AUTOSAR XML (schema 3.1.2)
package /Components/SWC_TqDem
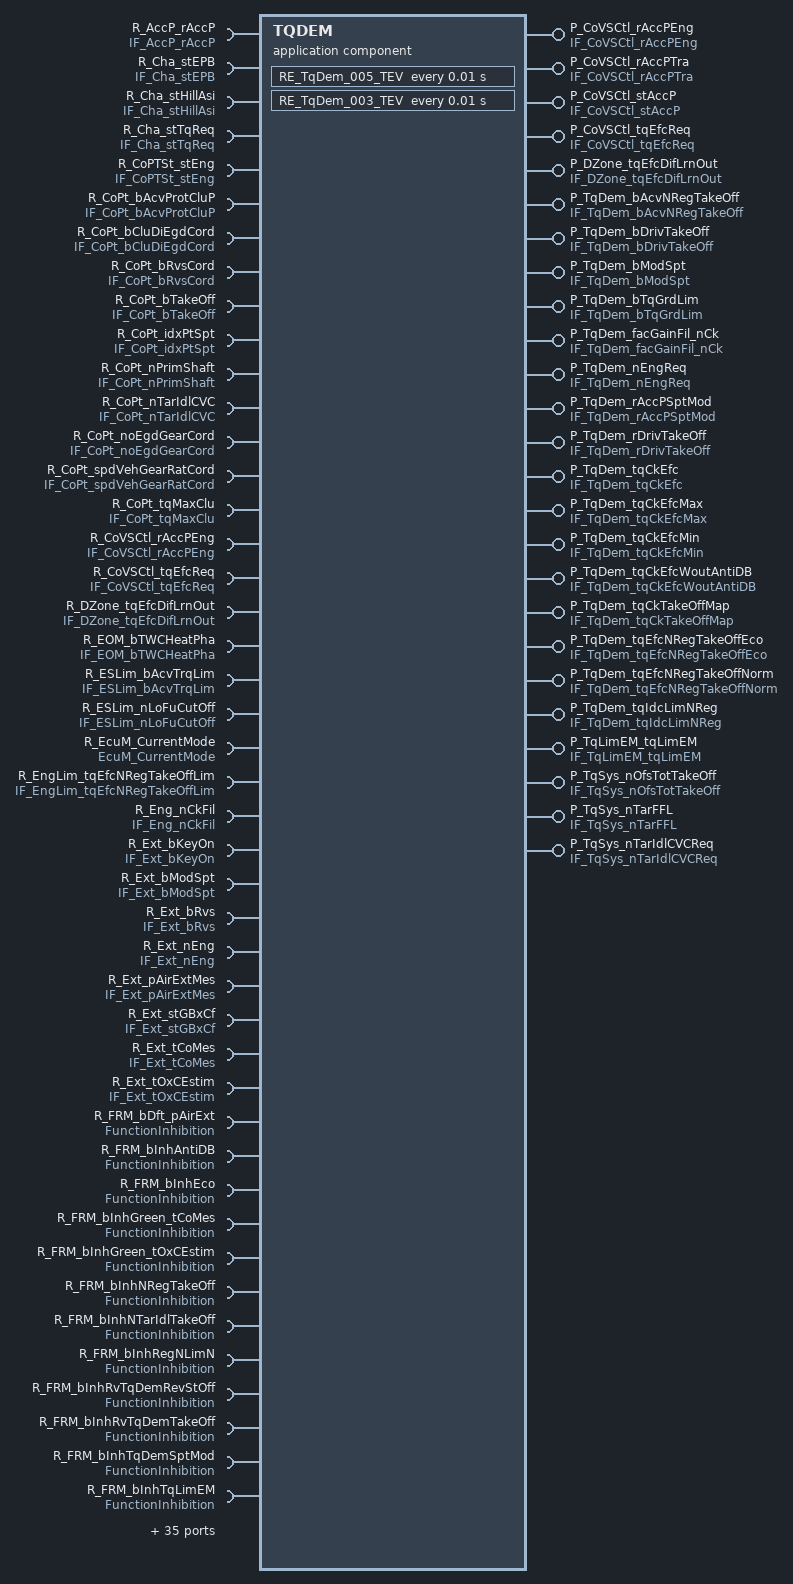
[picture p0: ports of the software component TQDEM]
  application software component type TQDEM  # TqDem
    25 x provide port:
      P_CoVSCtl_rAccPEng: unqueued-sender-com-spec{data-element=CoVSCtl_rAccPEng, can-invalidate=false, init-value=ConstantValue}, provided-interface=IF_CoVSCtl_rAccPEng
      P_CoVSCtl_rAccPTra: unqueued-sender-com-spec{data-element=CoVSCtl_rAccPTra, can-invalidate=false, init-value=ConstantValue1}, provided-interface=IF_CoVSCtl_rAccPTra
      P_CoVSCtl_stAccP: unqueued-sender-com-spec{data-element=CoVSCtl_stAccP, can-invalidate=false, init-value=ConstantValue3}, provided-interface=IF_CoVSCtl_stAccP
      P_CoVSCtl_tqEfcReq: unqueued-sender-com-spec{data-element=CoVSCtl_tqEfcReq, can-invalidate=false, init-value=ConstantValue5}, provided-interface=IF_CoVSCtl_tqEfcReq
      P_DZone_tqEfcDifLrnOut: unqueued-sender-com-spec{data-element=DZone_tqEfcDifLrnOut, can-invalidate=false, init-value=C_SInt16_0}, provided-interface=IF_DZone_tqEfcDifLrnOut
      P_TqDem_bAcvNRegTakeOff: unqueued-sender-com-spec{data-element=TqDem_bAcvNRegTakeOff, can-invalidate=false, init-value=C_Boolean_True}, provided-interface=IF_TqDem_bAcvNRegTakeOff
      P_TqDem_bDrivTakeOff: unqueued-sender-com-spec{data-element=TqDem_bDrivTakeOff, can-invalidate=false, init-value=ConstantValue7}, provided-interface=IF_TqDem_bDrivTakeOff
      P_TqDem_bModSpt: unqueued-sender-com-spec{data-element=TqDem_bModSpt, can-invalidate=false, init-value=ConstantValue9}, provided-interface=IF_TqDem_bModSpt
      P_TqDem_bTqGrdLim: unqueued-sender-com-spec{data-element=TqDem_bTqGrdLim, can-invalidate=false, init-value=ConstantValue11}, provided-interface=IF_TqDem_bTqGrdLim
      P_TqDem_facGainFil_nCk: unqueued-sender-com-spec{data-element=TqDem_facGainFil_nCk, can-invalidate=false, init-value=ConstantValue13}, provided-interface=IF_TqDem_facGainFil_nCk
      P_TqDem_nEngReq: unqueued-sender-com-spec{data-element=TqDem_nEngReq, can-invalidate=false, init-value=C_UInt16_750}, provided-interface=IF_TqDem_nEngReq
      P_TqDem_rAccPSptMod: unqueued-sender-com-spec{data-element=TqDem_rAccPSptMod, can-invalidate=false, init-value=C_UInt16_0}, provided-interface=IF_TqDem_rAccPSptMod
      P_TqDem_rDrivTakeOff: unqueued-sender-com-spec{data-element=TqDem_rDrivTakeOff, can-invalidate=false, init-value=C_UInt16_015}, provided-interface=IF_TqDem_rDrivTakeOff
      P_TqDem_tqCkEfc: unqueued-sender-com-spec{data-element=TqDem_tqCkEfc, can-invalidate=false, init-value=ConstantValue17}, provided-interface=IF_TqDem_tqCkEfc
      P_TqDem_tqCkEfcMax: unqueued-sender-com-spec{data-element=TqDem_tqCkEfcMax, can-invalidate=false, init-value=C_SInt16_019}, provided-interface=IF_TqDem_tqCkEfcMax
      P_TqDem_tqCkEfcMin: unqueued-sender-com-spec{data-element=TqDem_tqCkEfcMin, can-invalidate=false, init-value=C_SInt16_021}, provided-interface=IF_TqDem_tqCkEfcMin
      P_TqDem_tqCkEfcWoutAntiDB: unqueued-sender-com-spec{data-element=TqDem_tqCkEfcWoutAntiDB, can-invalidate=false, init-value=C_SInt16_023}, provided-interface=IF_TqDem_tqCkEfcWoutAntiDB
      P_TqDem_tqCkTakeOffMap: unqueued-sender-com-spec{data-element=TqDem_tqCkTakeOffMap, can-invalidate=false, init-value=C_SInt16_025}, provided-interface=IF_TqDem_tqCkTakeOffMap
      P_TqDem_tqEfcNRegTakeOffEco: unqueued-sender-com-spec{data-element=TqDem_tqEfcNRegTakeOffEco, can-invalidate=false, init-value=C_t_TqDem_Tab2_S16_0}, provided-interface=IF_TqDem_tqEfcNRegTakeOffEco
      P_TqDem_tqEfcNRegTakeOffNorm: unqueued-sender-com-spec{data-element=TqDem_tqEfcNRegTakeOffNorm, can-invalidate=false, init-value=C_t_TqDem_Tab2_S16_027}, provided-interface=IF_TqDem_tqEfcNRegTakeOffNorm
      P_TqDem_tqIdcLimNReg: unqueued-sender-com-spec{data-element=TqDem_tqIdcLimNReg, can-invalidate=false, init-value=ConstantValue29}, provided-interface=IF_TqDem_tqIdcLimNReg
      P_TqLimEM_tqLimEM: unqueued-sender-com-spec{data-element=TqLimEM_tqLimEM, can-invalidate=false, init-value=ConstantValue31}, provided-interface=IF_TqLimEM_tqLimEM
      P_TqSys_nOfsTotTakeOff: unqueued-sender-com-spec{data-element=TqSys_nOfsTotTakeOff, can-invalidate=false, init-value=C_UInt16_033}, provided-interface=IF_TqSys_nOfsTotTakeOff
      P_TqSys_nTarFFL: unqueued-sender-com-spec{data-element=TqSys_nTarFFL, can-invalidate=false, init-value=C_UInt16_035}, provided-interface=IF_TqSys_nTarFFL
      P_TqSys_nTarIdlCVCReq: unqueued-sender-com-spec{data-element=TqSys_nTarIdlCVCReq, can-invalidate=false, init-value=C_UInt16_037}, provided-interface=IF_TqSys_nTarIdlCVCReq
    79 x require port:
      R_AccP_rAccP: unqueued-receiver-com-spec{data-element=AccP_rAccP, init-value=ConstantValue39, resync-time=0}, required-interface=IF_AccP_rAccP
      R_Cha_stEPB: unqueued-receiver-com-spec{data-element=Cha_stEPB, init-value=ConstantValue41, resync-time=0}, required-interface=IF_Cha_stEPB
      R_Cha_stHillAsi: unqueued-receiver-com-spec{data-element=Cha_stHillAsi, init-value=C_UInt8_0, resync-time=0}, required-interface=IF_Cha_stHillAsi
      R_Cha_stTqReq: unqueued-receiver-com-spec{data-element=Cha_stTqReq, init-value=ConstantValue43, resync-time=0}, required-interface=IF_Cha_stTqReq
      R_CoPTSt_stEng: unqueued-receiver-com-spec{data-element=CoPTSt_stEng, init-value=ConstantValue45, resync-time=0}, required-interface=IF_CoPTSt_stEng
      R_CoPt_bAcvProtCluP: unqueued-receiver-com-spec{data-element=CoPt_bAcvProtCluP, init-value=C_Boolean_False, resync-time=0}, required-interface=IF_CoPt_bAcvProtCluP
      R_CoPt_bCluDiEgdCord: unqueued-receiver-com-spec{data-element=CoPt_bCluDiEgdCord, init-value=ConstantValue47, resync-time=0}, required-interface=IF_CoPt_bCluDiEgdCord
      R_CoPt_bRvsCord: unqueued-receiver-com-spec{data-element=CoPt_bRvsCord, init-value=ConstantValue49, resync-time=0}, required-interface=IF_CoPt_bRvsCord
      R_CoPt_bTakeOff: unqueued-receiver-com-spec{data-element=CoPt_bTakeOff, init-value=C_Boolean_False51, resync-time=0}, required-interface=IF_CoPt_bTakeOff
      R_CoPt_idxPtSpt: unqueued-receiver-com-spec{data-element=CoPt_idxPtSpt, init-value=C_UInt8_053, resync-time=0}, required-interface=IF_CoPt_idxPtSpt
      R_CoPt_nPrimShaft: unqueued-receiver-com-spec{data-element=CoPt_nPrimShaft, init-value=C_UInt16_055, resync-time=0}, required-interface=IF_CoPt_nPrimShaft
      R_CoPt_nTarIdlCVC: unqueued-receiver-com-spec{data-element=CoPt_nTarIdlCVC, init-value=C_UInt16_057, resync-time=0}, required-interface=IF_CoPt_nTarIdlCVC
      R_CoPt_noEgdGearCord: unqueued-receiver-com-spec{data-element=CoPt_noEgdGearCord, init-value=ConstantValue59, resync-time=0}, required-interface=IF_CoPt_noEgdGearCord
      R_CoPt_spdVehGearRatCord: unqueued-receiver-com-spec{data-element=CoPt_spdVehGearRatCord, init-value=ConstantValue61, resync-time=0}, required-interface=IF_CoPt_spdVehGearRatCord
      R_CoPt_tqMaxClu: unqueued-receiver-com-spec{data-element=CoPt_tqMaxClu, init-value=C_SInt16_m32000, resync-time=0}, required-interface=IF_CoPt_tqMaxClu
      R_CoVSCtl_rAccPEng: unqueued-receiver-com-spec{data-element=CoVSCtl_rAccPEng, init-value=ConstantValue, resync-time=0}, required-interface=IF_CoVSCtl_rAccPEng
      R_CoVSCtl_tqEfcReq: unqueued-receiver-com-spec{data-element=CoVSCtl_tqEfcReq, init-value=ConstantValue63, resync-time=0}, required-interface=IF_CoVSCtl_tqEfcReq
      R_DZone_tqEfcDifLrnOut: unqueued-receiver-com-spec{data-element=DZone_tqEfcDifLrnOut, init-value=C_SInt16_m3200065, resync-time=0}, required-interface=IF_DZone_tqEfcDifLrnOut
      R_EOM_bTWCHeatPha: unqueued-receiver-com-spec{data-element=EOM_bTWCHeatPha, init-value=ConstantValue67, resync-time=0}, required-interface=IF_EOM_bTWCHeatPha
      R_ESLim_bAcvTrqLim: unqueued-receiver-com-spec{data-element=ESLim_bAcvTrqLim, init-value=ConstantValue69, resync-time=0}, required-interface=IF_ESLim_bAcvTrqLim
      R_ESLim_nLoFuCutOff: unqueued-receiver-com-spec{data-element=ESLim_nLoFuCutOff, init-value=C_UInt16_071, resync-time=0}, required-interface=IF_ESLim_nLoFuCutOff
      R_EcuM_CurrentMode: required-interface=EcuM_CurrentMode  # Requirement: 01552_09_00532-SSTG-C007(2)
      R_EngLim_tqEfcNRegTakeOffLim: unqueued-receiver-com-spec{data-element=EngLim_tqEfcNRegTakeOffLim, init-value=C_SInt16_m3200073, resync-time=0}, required-interface=IF_EngLim_tqEfcNRegTakeOffLim
      R_Eng_nCkFil: unqueued-receiver-com-spec{data-element=Eng_nCkFil, init-value=ConstantValue75, resync-time=0}, required-interface=IF_Eng_nCkFil
      R_Ext_bKeyOn: unqueued-receiver-com-spec{data-element=Ext_bKeyOn, init-value=C_Boolean_False77, resync-time=0}, required-interface=IF_Ext_bKeyOn
      R_Ext_bModSpt: unqueued-receiver-com-spec{data-element=Ext_bModSpt, init-value=C_Boolean_False79, resync-time=0}, required-interface=IF_Ext_bModSpt
      R_Ext_bRvs: unqueued-receiver-com-spec{data-element=Ext_bRvs, init-value=ConstantValue81, resync-time=0}, required-interface=IF_Ext_bRvs
      R_Ext_nEng: unqueued-receiver-com-spec{data-element=Ext_nEng, init-value=ConstantValue83, resync-time=0}, required-interface=IF_Ext_nEng
      R_Ext_pAirExtMes: unqueued-receiver-com-spec{data-element=Ext_pAirExtMes, init-value=ConstantValue85, resync-time=0}, required-interface=IF_Ext_pAirExtMes
      R_Ext_stGBxCf: unqueued-receiver-com-spec{data-element=Ext_stGBxCf, init-value=ConstantValue87, resync-time=0}, required-interface=IF_Ext_stGBxCf
      R_Ext_tCoMes: unqueued-receiver-com-spec{data-element=Ext_tCoMes, init-value=ConstantValue89, resync-time=0}, required-interface=IF_Ext_tCoMes
      R_Ext_tOxCEstim: unqueued-receiver-com-spec{data-element=Ext_tOxCEstim, init-value=C_SInt16_m50, resync-time=0}, required-interface=IF_Ext_tOxCEstim
      R_FRM_bDft_pAirExt: required-interface=FunctionInhibition
      R_FRM_bInhAntiDB: required-interface=FunctionInhibition
      R_FRM_bInhEco: required-interface=FunctionInhibition
      R_FRM_bInhGreen_tCoMes: required-interface=FunctionInhibition
      R_FRM_bInhGreen_tOxCEstim: required-interface=FunctionInhibition
      R_FRM_bInhNRegTakeOff: required-interface=FunctionInhibition
      R_FRM_bInhNTarIdlTakeOff: required-interface=FunctionInhibition
      R_FRM_bInhRegNLimN: required-interface=FunctionInhibition
      R_FRM_bInhRvTqDemRevStOff: required-interface=FunctionInhibition
      R_FRM_bInhRvTqDemTakeOff: required-interface=FunctionInhibition
      R_FRM_bInhTqDemSptMod: required-interface=FunctionInhibition
      R_FRM_bInhTqLimEM: required-interface=FunctionInhibition
      R_TqAdp_bFrzAdpACOn: unqueued-receiver-com-spec{data-element=TqAdp_bFrzAdpACOn, init-value=ConstantValue91, resync-time=0}, required-interface=IF_TqAdp_bFrzAdpACOn
      R_TqAdp_bFrzAdpAltOn: unqueued-receiver-com-spec{data-element=TqAdp_bFrzAdpAltOn, init-value=ConstantValue93, resync-time=0}, required-interface=IF_TqAdp_bFrzAdpAltOn
      R_TqAdp_bFrzAdpCnvOn: unqueued-receiver-com-spec{data-element=TqAdp_bFrzAdpCnvOn, init-value=ConstantValue95, resync-time=0}, required-interface=IF_TqAdp_bFrzAdpCnvOn
      R_TqAdp_bFrzAdpStgPmpOn: unqueued-receiver-com-spec{data-element=TqAdp_bFrzAdpStgPmpOn, init-value=ConstantValue97, resync-time=0}, required-interface=IF_TqAdp_bFrzAdpStgPmpOn
      R_TqCmp_tqSumLossCmp: unqueued-receiver-com-spec{data-element=TqCmp_tqSumLossCmp, init-value=ConstantValue99, resync-time=0}, required-interface=IF_TqCmp_tqSumLossCmp
      R_TqDem_GetTimer_1ms_U32: required-interface=IF_CS_FRunTime_1MS_U32
      R_TqDem_bAcvNRegTakeOff: unqueued-receiver-com-spec{data-element=TqDem_bAcvNRegTakeOff, init-value=C_Boolean_False101, resync-time=0}, required-interface=IF_TqDem_bAcvNRegTakeOff
      R_TqDem_rAccPSptMod: unqueued-receiver-com-spec{data-element=TqDem_rAccPSptMod, init-value=C_UInt16_0, resync-time=0}, required-interface=IF_TqDem_rAccPSptMod
      R_TqDem_rDrivTakeOff: unqueued-receiver-com-spec{data-element=TqDem_rDrivTakeOff, init-value=C_UInt16_0103, resync-time=0}, required-interface=IF_TqDem_rDrivTakeOff
      R_TqDem_tqCkEfc: unqueued-receiver-com-spec{data-element=TqDem_tqCkEfc, init-value=ConstantValue105, resync-time=0}, required-interface=IF_TqDem_tqCkEfc
      R_TqDem_tqCkEfcWoutAntiDB: unqueued-receiver-com-spec{data-element=TqDem_tqCkEfcWoutAntiDB, init-value=C_SInt16_m32000107, resync-time=0}, required-interface=IF_TqDem_tqCkEfcWoutAntiDB
      R_TqDem_tqEfcNRegTakeOffEco: unqueued-receiver-com-spec{data-element=TqDem_tqEfcNRegTakeOffEco, init-value=C_t_TqDem_Tab2_S16_m32000, resync-time=0}, required-interface=IF_TqDem_tqEfcNRegTakeOffEco
      R_TqDem_tqEfcNRegTakeOffNorm: unqueued-receiver-com-spec{data-element=TqDem_tqEfcNRegTakeOffNorm, init-value=C_t_TqDem_Tab2_S16_m32000109, resync-time=0}, required-interface=IF_TqDem_tqEfcNRegTakeOffNorm
      R_TqSys_bAcvAntiStall: unqueued-receiver-com-spec{data-element=TqSys_bAcvAntiStall, init-value=ConstantValue111, resync-time=0}, required-interface=IF_TqSys_bAcvAntiStall
      R_TqSys_bAcvAntiStallMan: unqueued-receiver-com-spec{data-element=TqSys_bAcvAntiStallMan, init-value=ConstantValue113, resync-time=0}, required-interface=IF_TqSys_bAcvAntiStallMan
      R_TqSys_bEngNOnIdl: unqueued-receiver-com-spec{data-element=TqSys_bEngNOnIdl, init-value=ConstantValue115, resync-time=0}, required-interface=IF_TqSys_bEngNOnIdl
      R_TqSys_bInhTqDemSptMod: unqueued-receiver-com-spec{data-element=TqSys_bInhTqDemSptMod, init-value=C_Boolean_False117, resync-time=0}, required-interface=IF_TqSys_bInhTqDemSptMod
      R_TqSys_bTypFu: unqueued-receiver-com-spec{data-element=TqSys_bTypFu, init-value=ConstantValue119, resync-time=0}, required-interface=IF_TqSys_bTypFu
      R_TqSys_nOfsFFL: unqueued-receiver-com-spec{data-element=TqSys_nOfsFFL, init-value=C_UInt16_0121, resync-time=0}, required-interface=IF_TqSys_nOfsFFL
      R_TqSys_nOfsLauchIdlTakeOff: unqueued-receiver-com-spec{data-element=TqSys_nOfsLauchIdlTakeOff, init-value=C_UInt16_0123, resync-time=0}, required-interface=IF_TqSys_nOfsLauchIdlTakeOff
      R_TqSys_nOfsTotTakeOff: unqueued-receiver-com-spec{data-element=TqSys_nOfsTotTakeOff, init-value=C_UInt16_0125, resync-time=0}, required-interface=IF_TqSys_nOfsTotTakeOff
      R_TqSys_nTarIdl: unqueued-receiver-com-spec{data-element=TqSys_nTarIdl, init-value=ConstantValue127, resync-time=0}, required-interface=IF_TqSys_nTarIdl
      R_TqSys_nTarIdlFil: unqueued-receiver-com-spec{data-element=TqSys_nTarIdlFil, init-value=C_UInt16_0129, resync-time=0}, required-interface=IF_TqSys_nTarIdlFil
      R_TqSys_nTarIdlNeut: unqueued-receiver-com-spec{data-element=TqSys_nTarIdlNeut, init-value=C_UInt16_0131, resync-time=0}, required-interface=IF_TqSys_nTarIdlNeut
      R_TqSys_tqCkIdlCmn: unqueued-receiver-com-spec{data-element=TqSys_tqCkIdlCmn, init-value=ConstantValue133, resync-time=0}, required-interface=IF_TqSys_tqCkIdlCmn
      R_TqSys_tqIdcAirLimCordWiRes: unqueued-receiver-com-spec{data-element=TqSys_tqIdcAirLimCordWiRes, init-value=ConstantValue135, resync-time=0}, required-interface=IF_TqSys_tqIdcAirLimCordWiRes
      R_TreatTenms_nCkGrd: unqueued-receiver-com-spec{data-element=TreatTenms_nCkGrd, init-value=C_SInt16_m32000137, resync-time=0}, required-interface=IF_TreatTenms_nCkGrd
      R_UCE_stWkuMainRelSt: required-interface=IF_UCE_stWkuMainRelSt  # Requirement: 01552_09_00532-SSTG-C011(1)
      R_VSCtl_rAccPEngMax: unqueued-receiver-com-spec{data-element=VSCtl_rAccPEngMax, init-value=C_UInt16_0139, resync-time=0}, required-interface=IF_VSCtl_rAccPEngMax
      R_VSCtl_rAccPEngMin: unqueued-receiver-com-spec{data-element=VSCtl_rAccPEngMin, init-value=C_UInt16_0141, resync-time=0}, required-interface=IF_VSCtl_rAccPEngMin
      R_VSCtl_rAccPTraMax: unqueued-receiver-com-spec{data-element=VSCtl_rAccPTraMax, init-value=C_UInt16_0143, resync-time=0}, required-interface=IF_VSCtl_rAccPTraMax
      R_VSCtl_rAccPTraMin: unqueued-receiver-com-spec{data-element=VSCtl_rAccPTraMin, init-value=C_UInt16_0145, resync-time=0}, required-interface=IF_VSCtl_rAccPTraMin
      R_VSCtl_tqCkEfcMaxReq: unqueued-receiver-com-spec{data-element=VSCtl_tqCkEfcMaxReq, init-value=C_SInt16_m32000147, resync-time=0}, required-interface=IF_VSCtl_tqCkEfcMaxReq
      R_VSCtl_tqCkEfcMinReq: unqueued-receiver-com-spec{data-element=VSCtl_tqCkEfcMinReq, init-value=C_SInt16_m32000149, resync-time=0}, required-interface=IF_VSCtl_tqCkEfcMinReq
      R_Veh_spdVeh: unqueued-receiver-com-spec{data-element=Veh_spdVeh, init-value=ConstantValue151, resync-time=0}, required-interface=IF_Veh_spdVeh
  94 x constant specification:
    C_Boolean_False
      value:
        boolean literal C_Boolean_False: type=DT_CoPt_bAcvProtCluP, value=false
    C_Boolean_False101
      value:
        boolean literal C_Boolean_False101: type=DT_TqDem_bAcvNRegTakeOff, value=true
    C_Boolean_False117
      value:
        boolean literal C_Boolean_False117: type=DT_TqSys_bInhTqDemSptMod, value=false
    C_Boolean_False51
      value:
        boolean literal C_Boolean_False51: type=DT_CoPt_bTakeOff, value=false
    C_Boolean_False77
      value:
        boolean literal C_Boolean_False77: type=DT_Ext_bKeyOn, value=false
    C_Boolean_False79
      value:
        boolean literal C_Boolean_False79: type=DT_Ext_bModSpt, value=false
    C_Boolean_True
      value:
        boolean literal C_Boolean_True: type=DT_TqDem_bAcvNRegTakeOff, value=true
    C_SInt16_0
      value:
        integer literal C_SInt16_0: type=DT_DZone_tqEfcDifLrnOut, value=0
    C_SInt16_0153
      value:
        integer literal C_SInt16_0153: type=DT_TqDem_tqCkEfcDeltaEcoNorm, value=0
    C_SInt16_0155
      value:
        integer literal C_SInt16_0155: type=DT_TqDem_tqCkEfcDeltaTakeOff, value=0
    C_SInt16_019
      value:
        integer literal C_SInt16_019: type=DT_TqDem_tqCkEfcMax, value=0
    C_SInt16_021
      value:
        integer literal C_SInt16_021: type=DT_TqDem_tqCkEfcMin, value=0
    C_SInt16_023
      value:
        integer literal C_SInt16_023: type=DT_TqDem_tqCkEfcWoutAntiDB, value=0
    C_SInt16_025
      value:
        integer literal C_SInt16_025: type=DT_TqDem_tqCkTakeOffMap, value=0
    C_SInt16_m32000
      value:
        integer literal C_SInt16_m32000: type=DT_CoPt_tqMaxClu, value=0
    C_SInt16_m32000107
      value:
        integer literal C_SInt16_m32000107: type=DT_TqDem_tqCkEfcWoutAntiDB, value=0
    C_SInt16_m32000137
      value:
        integer literal C_SInt16_m32000137: type=DT_TreatTenms_nCkGrd, value=0
    C_SInt16_m32000147
      value:
        integer literal C_SInt16_m32000147: type=DT_VSCtl_tqCkEfcMaxReq, value=32000
    C_SInt16_m32000149
      value:
        integer literal C_SInt16_m32000149: type=DT_VSCtl_tqCkEfcMinReq, value=-32000
    C_SInt16_m3200065
      value:
        integer literal C_SInt16_m3200065: type=DT_DZone_tqEfcDifLrnOut, value=0
    C_SInt16_m3200073
      value:
        integer literal C_SInt16_m3200073: type=DT_EngLim_tqEfcNRegTakeOffLim, value=32000
    C_SInt16_m50
      value:
        integer literal C_SInt16_m50: type=DT_Ext_tOxCEstim, value=1000
    C_t_TqDem_Tab2_S16_0
      value:
        array specification C_t_TqDem_Tab2_S16_0: type=t_TqDem_Tab2_S16
          integer literal Value_0: type=DT_TqDem_tqEfcNRegTakeOffEco, value=0
          integer literal Value_1: type=DT_TqDem_tqEfcNRegTakeOffEco, value=0
    C_t_TqDem_Tab2_S16_027
      value:
        array specification C_t_TqDem_Tab2_S16_027: type=t_TqDem_Tab2_S16_m1
          integer literal Value_0: type=DT_TqDem_tqEfcNRegTakeOffNorm, value=0
          integer literal Value_1: type=DT_TqDem_tqEfcNRegTakeOffNorm, value=0
    C_t_TqDem_Tab2_S16_m32000
      value:
        array specification C_t_TqDem_Tab2_S16_m32000: type=t_TqDem_Tab2_S16
          integer literal Value_0: type=DT_TqDem_tqEfcNRegTakeOffEco, value=0
          integer literal Value_1: type=DT_TqDem_tqEfcNRegTakeOffEco, value=0
    C_t_TqDem_Tab2_S16_m32000109
      value:
        array specification C_t_TqDem_Tab2_S16_m32000109: type=t_TqDem_Tab2_S16_m1
          integer literal Value_0: type=DT_TqDem_tqEfcNRegTakeOffNorm, value=0
          integer literal Value_1: type=DT_TqDem_tqEfcNRegTakeOffNorm, value=0
    C_UInt16_0
      value:
        integer literal C_UInt16_0: type=DT_TqDem_rAccPSptMod, value=0
    C_UInt16_0103
      value:
        integer literal C_UInt16_0103: type=DT_TqDem_rDrivTakeOff, value=0
    C_UInt16_0121
      value:
        integer literal C_UInt16_0121: type=DT_TqSys_nOfsFFL, value=0
    C_UInt16_0123
      value:
        integer literal C_UInt16_0123: type=DT_TqSys_nOfsLauchIdlTakeOff, value=0
    C_UInt16_0125
      value:
        integer literal C_UInt16_0125: type=DT_TqSys_nOfsTotTakeOff, value=0
    C_UInt16_0129
      value:
        integer literal C_UInt16_0129: type=DT_TqSys_nTarIdlFil, value=0
    C_UInt16_0131
      value:
        integer literal C_UInt16_0131: type=DT_TqSys_nTarIdlNeut, value=0
    C_UInt16_0139
      value:
        integer literal C_UInt16_0139: type=DT_VSCtl_rAccPEngMax, value=12800
    C_UInt16_0141
      value:
        integer literal C_UInt16_0141: type=DT_VSCtl_rAccPEngMin, value=0
    C_UInt16_0143
      value:
        integer literal C_UInt16_0143: type=DT_VSCtl_rAccPTraMax, value=0
    C_UInt16_0145
      value:
        integer literal C_UInt16_0145: type=DT_VSCtl_rAccPTraMin, value=0
    C_UInt16_015
      value:
        integer literal C_UInt16_015: type=DT_TqDem_rDrivTakeOff, value=0
    C_UInt16_0157
      value:
        integer literal C_UInt16_0157: type=DT_TqDem_rTranEcoNorm, value=0
    C_UInt16_0159
      value:
        integer literal C_UInt16_0159: type=DT_TqDem_rTranDrv, value=0
    C_UInt16_033
      value:
        integer literal C_UInt16_033: type=DT_TqSys_nOfsTotTakeOff, value=0
    C_UInt16_035
      value:
        integer literal C_UInt16_035: type=DT_TqSys_nTarFFL, value=0
    C_UInt16_037
      value:
        integer literal C_UInt16_037: type=DT_TqSys_nTarIdlCVCReq, value=0
    C_UInt16_055
      value:
        integer literal C_UInt16_055: type=DT_CoPt_nPrimShaft, value=0
    C_UInt16_057
      value:
        integer literal C_UInt16_057: type=DT_CoPt_nTarIdlCVC, value=0
    C_UInt16_071
      value:
        integer literal C_UInt16_071: type=DT_ESLim_nLoFuCutOff, value=5500
    C_UInt16_750
      value:
        integer literal C_UInt16_750: type=DT_TqDem_nEngReq, value=750
    C_UInt8_0
      value:
        integer literal C_UInt8_0: type=DT_Cha_stHillAsi, value=0
    C_UInt8_053
      value:
        integer literal C_UInt8_053: type=DT_CoPt_idxPtSpt, value=0
    C_UInt8_1
      value:
        integer literal C_UInt8_1: type=DT_TqDem_idxMapTranDrvSec, value=1
    C_UInt8_1161
      value:
        integer literal C_UInt8_1161: type=DT_TqDem_idxMapTranDrvFirst, value=1
    C_UInt8_5
      value:
        integer literal C_UInt8_5: type=DT_TqDem_idxMapRvsDrv, value=5
    ConstantValue
      value:
        integer literal ConstantValue: type=DT_CoVSCtl_rAccPEng, value=0
    ConstantValue1
      value:
        integer literal ConstantValue1: type=DT_CoVSCtl_rAccPTra, value=0
    ConstantValue105
      value:
        integer literal ConstantValue105: type=DT_TqDem_tqCkEfc, value=0
    ConstantValue11
      value:
        boolean literal ConstantValue11: type=DT_TqDem_bTqGrdLim, value=false
    ConstantValue111
      value:
        boolean literal ConstantValue111: type=DT_TqSys_bAcvAntiStall, value=true
    ConstantValue113
      value:
        boolean literal ConstantValue113: type=DT_TqSys_bAcvAntiStallMan, value=false
    ConstantValue115
      value:
        boolean literal ConstantValue115: type=DT_TqSys_bEngNOnIdl, value=true
    ConstantValue119
      value:
        boolean literal ConstantValue119: type=DT_TqSys_bTypFu, value=false
    ConstantValue127
      value:
        integer literal ConstantValue127: type=DT_TqSys_nTarIdl, value=0
    ConstantValue13
      value:
        integer literal ConstantValue13: type=DT_TqDem_facGainFil_nCk, value=0
    ConstantValue133
      value:
        integer literal ConstantValue133: type=DT_TqSys_tqCkIdlCmn, value=0
    ConstantValue135
      value:
        integer literal ConstantValue135: type=DT_TqSys_tqIdcAirLimCordWiRes, value=0
    ConstantValue151
      value:
        integer literal ConstantValue151: type=DT_Veh_spdVeh, value=0
    ConstantValue17
      value:
        integer literal ConstantValue17: type=DT_TqDem_tqCkEfc, value=0
    ConstantValue29
      value:
        integer literal ConstantValue29: type=DT_TqDem_tqIdcLimNReg, value=0
    ConstantValue3
      value:
        integer literal ConstantValue3: type=DT_CoVSCtl_stAccP, value=0
    ConstantValue31
      value:
        integer literal ConstantValue31: type=DT_TqLimEM_tqLimEM, value=0
    ConstantValue39
      value:
        integer literal ConstantValue39: type=DT_AccP_rAccP, value=0
    ConstantValue41
      value:
        integer literal ConstantValue41: type=DT_Cha_stEPB, value=0
    ConstantValue43
      value:
        integer literal ConstantValue43: type=DT_Cha_stTqReq, value=0
    ConstantValue45
      value:
        integer literal ConstantValue45: type=DT_CoPTSt_stEng, value=1
    ConstantValue47
      value:
        boolean literal ConstantValue47: type=DT_CoPt_bCluDiEgdCord, value=false
    ConstantValue49
      value:
        boolean literal ConstantValue49: type=DT_CoPt_bRvsCord, value=false
    ConstantValue5
      value:
        integer literal ConstantValue5: type=DT_CoVSCtl_tqEfcReq, value=0
    ConstantValue59
      value:
        integer literal ConstantValue59: type=DT_CoPt_noEgdGearCord, value=0
    ConstantValue61
      value:
        integer literal ConstantValue61: type=DT_CoPt_spdVehGearRatCord, value=0
    ConstantValue63
      value:
        integer literal ConstantValue63: type=DT_CoVSCtl_tqEfcReq, value=0
    ConstantValue67
      value:
        boolean literal ConstantValue67: type=DT_EOM_bTWCHeatPha, value=false
    ConstantValue69
      value:
        boolean literal ConstantValue69: type=DT_ESLim_bAcvTrqLim, value=false
    ConstantValue7
      value:
        boolean literal ConstantValue7: type=DT_TqDem_bDrivTakeOff, value=false
    ConstantValue75
      value:
        integer literal ConstantValue75: type=DT_Eng_nCkFil, value=0
    ConstantValue81
      value:
        boolean literal ConstantValue81: type=DT_Ext_bRvs, value=false
    ConstantValue83
      value:
        integer literal ConstantValue83: type=DT_Ext_nEng, value=0
    ConstantValue85
      value:
        integer literal ConstantValue85: type=DT_Ext_pAirExtMes, value=500
    ConstantValue87
      value:
        integer literal ConstantValue87: type=DT_Ext_stGBxCf, value=0
    ConstantValue89
      value:
        integer literal ConstantValue89: type=DT_Ext_tCoMes, value=20
    ConstantValue9
      value:
        boolean literal ConstantValue9: type=DT_TqDem_bModSpt, value=false
    ConstantValue91
      value:
        boolean literal ConstantValue91: type=DT_TqAdp_bFrzAdpACOn, value=false
    ConstantValue93
      value:
        boolean literal ConstantValue93: type=DT_TqAdp_bFrzAdpAltOn, value=false
    ConstantValue95
      value:
        boolean literal ConstantValue95: type=DT_TqAdp_bFrzAdpCnvOn, value=false
    ConstantValue97
      value:
        boolean literal ConstantValue97: type=DT_TqAdp_bFrzAdpStgPmpOn, value=false
    ConstantValue99
      value:
        integer literal ConstantValue99: type=DT_TqCmp_tqSumLossCmp, value=0
  internal behavior IB_TqDem: component=TQDEM
    timing event EV_TqSys_Sdl10ms_TqTOff: mode-dependency=dependent-on-mode=[R_UCE_stWkuMainRelSt.RCD_stWkuMainRelSt.Invalid, R_UCE_stWkuMainRelSt.RCD_stWkuMainRelSt.PostMainWakeUp, R_UCE_stWkuMainRelSt.RCD_stWkuMainRelSt.PreMainWakeUp], start-on-event=RE_TqDem_005_TEV, period=0.01
    timing event EV_TqSys_Sdl10ms_TqDemStruct: mode-dependency=dependent-on-mode=[R_UCE_stWkuMainRelSt.RCD_stWkuMainRelSt.Invalid, R_UCE_stWkuMainRelSt.RCD_stWkuMainRelSt.PostMainWakeUp, R_UCE_stWkuMainRelSt.RCD_stWkuMainRelSt.PreMainWakeUp], start-on-event=RE_TqDem_003_TEV, period=0.01
    mode switch event EV_TqDem_001_MSE: start-on-event=RE_TqDem_001_MSE, activation=ENTRY, mode=R_EcuM_CurrentMode.currentMode.RUN
    5 x timing event, all with mode-dependency=dependent-on-mode=[R_UCE_stWkuMainRelSt.RCD_stWkuMainRelSt.Invalid, R_UCE_stWkuMainRelSt.RCD_stWkuMainRelSt.PostMainWakeUp, R_UCE_stWkuMainRelSt.RCD_stWkuMainRelSt.PreMainWakeUp], period=0.01:
      EV_TqSys_Sdl10ms_TqLimEM: start-on-event=RE_TqDem_008_TEV
      EV_TqSys_Sdl10ms_TqDemCont: start-on-event=RE_TqDem_004_TEV
      EV_TqSys_Sdl10ms_AntiDB: start-on-event=RE_TqDem_002_TEV
      EV_TqSys_Sdl10ms_CoVSCtl: start-on-event=RE_TqDem_007_TEV
      EV_TqSys_Sdl10ms_NEngTOff: start-on-event=RE_TqDem_006_TEV
    7 x inter runnable variable, all with sw-calibration-access=READ-WRITE, communication-approach=EXPLICIT:
      TqDem_idxMapRvsDrv: type=DT_TqDem_idxMapRvsDrv, init-value=C_UInt8_5
      TqDem_tqCkEfcDeltaTakeOff: type=DT_TqDem_tqCkEfcDeltaTakeOff, init-value=C_SInt16_0155
      TqDem_tqCkEfcDeltaEcoNorm: type=DT_TqDem_tqCkEfcDeltaEcoNorm, init-value=C_SInt16_0153
      TqDem_idxMapTranDrvFirst: type=DT_TqDem_idxMapTranDrvFirst, init-value=C_UInt8_1161
      TqDem_rTranEcoNorm: type=DT_TqDem_rTranEcoNorm, init-value=C_UInt16_0157
      TqDem_idxMapTranDrvSec: type=DT_TqDem_idxMapTranDrvSec, init-value=C_UInt8_1
      TqDem_rTranDrv: type=DT_TqDem_rTranDrv, init-value=C_UInt16_0159
    8 x runnable:
      RE_TqDem_007_TEV  # RE_062026_10ms
        9 x data receive point:
          dr_VSCtl_rAccPTraMax: data-element=R_VSCtl_rAccPTraMax.VSCtl_rAccPTraMax
          dr_VSCtl_rAccPEngMax: data-element=R_VSCtl_rAccPEngMax.VSCtl_rAccPEngMax
          dr_VSCtl_tqCkEfcMaxReq: data-element=R_VSCtl_tqCkEfcMaxReq.VSCtl_tqCkEfcMaxReq
          dr_VSCtl_rAccPEngMin: data-element=R_VSCtl_rAccPEngMin.VSCtl_rAccPEngMin
          dr_TqDem_rAccPSptMod: data-element=R_TqDem_rAccPSptMod.TqDem_rAccPSptMod
          dr_TqDem_tqCkEfc: data-element=R_TqDem_tqCkEfc.TqDem_tqCkEfc
          dr_VSCtl_rAccPTraMin: data-element=R_VSCtl_rAccPTraMin.VSCtl_rAccPTraMin
          dr_VSCtl_tqCkEfcMinReq: data-element=R_VSCtl_tqCkEfcMinReq.VSCtl_tqCkEfcMinReq
          dr_AccP_rAccP: data-element=R_AccP_rAccP.AccP_rAccP
        4 x data send point:
          ds_CoVSCtl_rAccPEng: data-element=P_CoVSCtl_rAccPEng.CoVSCtl_rAccPEng
          ds_CoVSCtl_tqEfcReq: data-element=P_CoVSCtl_tqEfcReq.CoVSCtl_tqEfcReq
          ds_CoVSCtl_rAccPTra: data-element=P_CoVSCtl_rAccPTra.CoVSCtl_rAccPTra
          ds_CoVSCtl_stAccP: data-element=P_CoVSCtl_stAccP.CoVSCtl_stAccP
        sync call ssp_GetTimer_1ms_U32: operation=R_TqDem_GetTimer_1ms_U32.GetTimer_1ms_U32
      RE_TqDem_001_MSE: written-variable=[TqDem_idxMapRvsDrv, TqDem_rTranEcoNorm, TqDem_tqCkEfcDeltaTakeOff, TqDem_tqCkEfcDeltaEcoNorm, TqDem_idxMapTranDrvFirst, TqDem_rTranDrv, TqDem_idxMapTranDrvSec]  # -
        25 x data send point:
          ds_CoVSCtl_rAccPEng: data-element=P_CoVSCtl_rAccPEng.CoVSCtl_rAccPEng
          ds_TqSys_nTarFFL: data-element=P_TqSys_nTarFFL.TqSys_nTarFFL
          ds_TqDem_rAccPSptMod: data-element=P_TqDem_rAccPSptMod.TqDem_rAccPSptMod
          ds_DZone_tqEfcDifLrnOut: data-element=P_DZone_tqEfcDifLrnOut.DZone_tqEfcDifLrnOut
          ds_TqDem_tqCkEfcMax: data-element=P_TqDem_tqCkEfcMax.TqDem_tqCkEfcMax
          ds_TqDem_bDrivTakeOff: data-element=P_TqDem_bDrivTakeOff.TqDem_bDrivTakeOff
          ds_TqDem_tqIdcLimNReg: data-element=P_TqDem_tqIdcLimNReg.TqDem_tqIdcLimNReg
          ds_TqDem_bModSpt: data-element=P_TqDem_bModSpt.TqDem_bModSpt
          ds_TqDem_tqCkEfcWoutAntiDB: data-element=P_TqDem_tqCkEfcWoutAntiDB.TqDem_tqCkEfcWoutAntiDB
          ds_TqLimEM_tqLimEM: data-element=P_TqLimEM_tqLimEM.TqLimEM_tqLimEM
          ds_TqDem_rDrivTakeOff: data-element=P_TqDem_rDrivTakeOff.TqDem_rDrivTakeOff
          ds_TqSys_nTarIdlCVCReq: data-element=P_TqSys_nTarIdlCVCReq.TqSys_nTarIdlCVCReq
          ds_TqDem_tqCkEfc: data-element=P_TqDem_tqCkEfc.TqDem_tqCkEfc
          ds_TqDem_facGainFil_nCk: data-element=P_TqDem_facGainFil_nCk.TqDem_facGainFil_nCk
          ds_TqSys_nOfsTotTakeOff: data-element=P_TqSys_nOfsTotTakeOff.TqSys_nOfsTotTakeOff
          ds_TqDem_tqEfcNRegTakeOffEco: data-element=P_TqDem_tqEfcNRegTakeOffEco.TqDem_tqEfcNRegTakeOffEco
          ds_TqDem_tqCkTakeOffMap: data-element=P_TqDem_tqCkTakeOffMap.TqDem_tqCkTakeOffMap
          ds_TqDem_nEngReq: data-element=P_TqDem_nEngReq.TqDem_nEngReq
          ds_TqDem_bTqGrdLim: data-element=P_TqDem_bTqGrdLim.TqDem_bTqGrdLim
          ds_CoVSCtl_tqEfcReq: data-element=P_CoVSCtl_tqEfcReq.CoVSCtl_tqEfcReq
          ds_TqDem_bAcvNRegTakeOff: data-element=P_TqDem_bAcvNRegTakeOff.TqDem_bAcvNRegTakeOff
          ds_TqDem_tqEfcNRegTakeOffNorm: data-element=P_TqDem_tqEfcNRegTakeOffNorm.TqDem_tqEfcNRegTakeOffNorm
          ds_CoVSCtl_stAccP: data-element=P_CoVSCtl_stAccP.CoVSCtl_stAccP
          ds_CoVSCtl_rAccPTra: data-element=P_CoVSCtl_rAccPTra.CoVSCtl_rAccPTra
          ds_TqDem_tqCkEfcMin: data-element=P_TqDem_tqCkEfcMin.TqDem_tqCkEfcMin
        sync call ssp_GetTimer_1ms_U32: operation=R_TqDem_GetTimer_1ms_U32.GetTimer_1ms_U32
      RE_TqDem_006_TEV  # RE_080091_10ms
        11 x data receive point:
          dr_TqSys_nOfsLauchIdlTakeOff: data-element=R_TqSys_nOfsLauchIdlTakeOff.TqSys_nOfsLauchIdlTakeOff
          dr_TqSys_nOfsFFL: data-element=R_TqSys_nOfsFFL.TqSys_nOfsFFL
          dr_CoPt_bCluDiEgdCord: data-element=R_CoPt_bCluDiEgdCord.CoPt_bCluDiEgdCord
          dr_Ext_pAirExtMes: data-element=R_Ext_pAirExtMes.Ext_pAirExtMes
          dr_TqSys_nTarIdlNeut: data-element=R_TqSys_nTarIdlNeut.TqSys_nTarIdlNeut
          dr_CoPt_nTarIdlCVC: data-element=R_CoPt_nTarIdlCVC.CoPt_nTarIdlCVC
          dr_TqSys_bAcvAntiStallMan: data-element=R_TqSys_bAcvAntiStallMan.TqSys_bAcvAntiStallMan
          dr_Cha_stTqReq: data-element=R_Cha_stTqReq.Cha_stTqReq
          dr_Veh_spdVeh: data-element=R_Veh_spdVeh.Veh_spdVeh
          dr_CoVSCtl_rAccPEng: data-element=R_CoVSCtl_rAccPEng.CoVSCtl_rAccPEng
          dr_TqSys_nTarIdlFil: data-element=R_TqSys_nTarIdlFil.TqSys_nTarIdlFil
        data send point ds_TqSys_nTarFFL: data-element=P_TqSys_nTarFFL.TqSys_nTarFFL
        data send point ds_TqSys_nTarIdlCVCReq: data-element=P_TqSys_nTarIdlCVCReq.TqSys_nTarIdlCVCReq
        data send point ds_TqSys_nOfsTotTakeOff: data-element=P_TqSys_nOfsTotTakeOff.TqSys_nOfsTotTakeOff
        sync call ssp_FRM_bDft_pAirExt: operation=R_FRM_bDft_pAirExt.GetFunctionPermission
        sync call ssp_GetTimer_1ms_U32: operation=R_TqDem_GetTimer_1ms_U32.GetTimer_1ms_U32
        sync call ssp_FRM_bInhNTarIdlTakeOff: operation=R_FRM_bInhNTarIdlTakeOff.GetFunctionPermission
      RE_TqDem_002_TEV  # RE_062030_10ms_init
        16 x data receive point:
          dr_CoPTSt_stEng: data-element=R_CoPTSt_stEng.CoPTSt_stEng
          dr_CoVSCtl_rAccPEng: data-element=R_CoVSCtl_rAccPEng.CoVSCtl_rAccPEng
          dr_TqSys_tqCkIdlCmn: data-element=R_TqSys_tqCkIdlCmn.TqSys_tqCkIdlCmn
          dr_CoPt_noEgdGearCord: data-element=R_CoPt_noEgdGearCord.CoPt_noEgdGearCord
          dr_TqSys_bEngNOnIdl: data-element=R_TqSys_bEngNOnIdl.TqSys_bEngNOnIdl
          dr_TqSys_nTarIdl: data-element=R_TqSys_nTarIdl.TqSys_nTarIdl
          dr_TqAdp_bFrzAdpACOn: data-element=R_TqAdp_bFrzAdpACOn.TqAdp_bFrzAdpACOn
          dr_TqAdp_bFrzAdpAltOn: data-element=R_TqAdp_bFrzAdpAltOn.TqAdp_bFrzAdpAltOn
          dr_Veh_spdVeh: data-element=R_Veh_spdVeh.Veh_spdVeh
          dr_TqCmp_tqSumLossCmp: data-element=R_TqCmp_tqSumLossCmp.TqCmp_tqSumLossCmp
          dr_Eng_nCkFil: data-element=R_Eng_nCkFil.Eng_nCkFil
          dr_TqAdp_bFrzAdpCnvOn: data-element=R_TqAdp_bFrzAdpCnvOn.TqAdp_bFrzAdpCnvOn
          dr_TqSys_bAcvAntiStall: data-element=R_TqSys_bAcvAntiStall.TqSys_bAcvAntiStall
          dr_TqSys_nOfsTotTakeOff: data-element=R_TqSys_nOfsTotTakeOff.TqSys_nOfsTotTakeOff
          dr_TqAdp_bFrzAdpStgPmpOn: data-element=R_TqAdp_bFrzAdpStgPmpOn.TqAdp_bFrzAdpStgPmpOn
          dr_TqDem_tqCkEfcWoutAntiDB: data-element=R_TqDem_tqCkEfcWoutAntiDB.TqDem_tqCkEfcWoutAntiDB
        data send point ds_DZone_tqEfcDifLrnOut: data-element=P_DZone_tqEfcDifLrnOut.DZone_tqEfcDifLrnOut
        sync call ssp_FRM_bInhAntiDB: operation=R_FRM_bInhAntiDB.GetFunctionPermission
        sync call ssp_GetTimer_1ms_U32: operation=R_TqDem_GetTimer_1ms_U32.GetTimer_1ms_U32
      RE_TqDem_008_TEV  # RE_062031_10ms
        6 x data receive point:
          dr_CoPTSt_stEng: data-element=R_CoPTSt_stEng.CoPTSt_stEng
          dr_CoVSCtl_tqEfcReq: data-element=R_CoVSCtl_tqEfcReq.CoVSCtl_tqEfcReq
          dr_Cha_stHillAsi: data-element=R_Cha_stHillAsi.Cha_stHillAsi
          dr_Cha_stEPB: data-element=R_Cha_stEPB.Cha_stEPB
          dr_CoPt_noEgdGearCord: data-element=R_CoPt_noEgdGearCord.CoPt_noEgdGearCord
          dr_Ext_stGBxCf: data-element=R_Ext_stGBxCf.Ext_stGBxCf
        data send point ds_TqLimEM_tqLimEM: data-element=P_TqLimEM_tqLimEM.TqLimEM_tqLimEM
        sync call ssp_FRM_bInhTqLimEM: operation=R_FRM_bInhTqLimEM.GetFunctionPermission
        sync call ssp_GetTimer_1ms_U32: operation=R_TqDem_GetTimer_1ms_U32.GetTimer_1ms_U32
      RE_TqDem_005_TEV  # RE_080919_10ms
        21 x data receive point:
          dr_TqSys_bEngNOnIdl: data-element=R_TqSys_bEngNOnIdl.TqSys_bEngNOnIdl
          dr_CoPt_tqMaxClu: data-element=R_CoPt_tqMaxClu.CoPt_tqMaxClu
          dr_TqDem_tqCkEfc: data-element=R_TqDem_tqCkEfc.TqDem_tqCkEfc
          dr_Eng_nCkFil: data-element=R_Eng_nCkFil.Eng_nCkFil
          dr_TqDem_rDrivTakeOff: data-element=R_TqDem_rDrivTakeOff.TqDem_rDrivTakeOff
          dr_TreatTenms_nCkGrd: data-element=R_TreatTenms_nCkGrd.TreatTenms_nCkGrd
          dr_CoPt_bAcvProtCluP: data-element=R_CoPt_bAcvProtCluP.CoPt_bAcvProtCluP
          dr_CoPt_nPrimShaft: data-element=R_CoPt_nPrimShaft.CoPt_nPrimShaft
          dr_TqDem_rAccPSptMod: data-element=R_TqDem_rAccPSptMod.TqDem_rAccPSptMod
          dr_ESLim_nLoFuCutOff: data-element=R_ESLim_nLoFuCutOff.ESLim_nLoFuCutOff
          dr_ESLim_bAcvTrqLim: data-element=R_ESLim_bAcvTrqLim.ESLim_bAcvTrqLim
          dr_AccP_rAccP: data-element=R_AccP_rAccP.AccP_rAccP
          dr_EngLim_tqEfcNRegTakeOffLim: data-element=R_EngLim_tqEfcNRegTakeOffLim.EngLim_tqEfcNRegTakeOffLim
          dr_TqSys_nTarIdl: data-element=R_TqSys_nTarIdl.TqSys_nTarIdl
          dr_Veh_spdVeh: data-element=R_Veh_spdVeh.Veh_spdVeh
          dr_CoPt_bRvsCord: data-element=R_CoPt_bRvsCord.CoPt_bRvsCord
          dr_Ext_nEng: data-element=R_Ext_nEng.Ext_nEng
          dr_Ext_tCoMes: data-element=R_Ext_tCoMes.Ext_tCoMes
          dr_TqSys_tqIdcAirLimCordWiRes: data-element=R_TqSys_tqIdcAirLimCordWiRes.TqSys_tqIdcAirLimCordWiRes
          dr_TqCmp_tqSumLossCmp: data-element=R_TqCmp_tqSumLossCmp.TqCmp_tqSumLossCmp
          dr_CoPt_noEgdGearCord: data-element=R_CoPt_noEgdGearCord.CoPt_noEgdGearCord
        5 x data send point:
          ds_TqDem_tqEfcNRegTakeOffNorm: data-element=P_TqDem_tqEfcNRegTakeOffNorm.TqDem_tqEfcNRegTakeOffNorm
          ds_TqDem_bAcvNRegTakeOff: data-element=P_TqDem_bAcvNRegTakeOff.TqDem_bAcvNRegTakeOff
          ds_TqDem_tqEfcNRegTakeOffEco: data-element=P_TqDem_tqEfcNRegTakeOffEco.TqDem_tqEfcNRegTakeOffEco
          ds_TqDem_nEngReq: data-element=P_TqDem_nEngReq.TqDem_nEngReq
          ds_TqDem_tqIdcLimNReg: data-element=P_TqDem_tqIdcLimNReg.TqDem_tqIdcLimNReg
        sync call ssp_FRM_bInhRegNLimN: operation=R_FRM_bInhRegNLimN.GetFunctionPermission
        sync call ssp_GetTimer_1ms_U32: operation=R_TqDem_GetTimer_1ms_U32.GetTimer_1ms_U32
        sync call ssp_FRM_bInhNRegTakeOff: operation=R_FRM_bInhNRegTakeOff.GetFunctionPermission
      RE_TqDem_004_TEV: read-variable=[TqDem_idxMapTranDrvSec, TqDem_idxMapTranDrvFirst, TqDem_rTranDrv, TqDem_idxMapRvsDrv, TqDem_rTranEcoNorm], written-variable=[TqDem_tqCkEfcDeltaEcoNorm, TqDem_tqCkEfcDeltaTakeOff]  # RE_060062_10ms
        15 x data receive point:
          dr_CoPt_noEgdGearCord: data-element=R_CoPt_noEgdGearCord.CoPt_noEgdGearCord
          dr_TqCmp_tqSumLossCmp: data-element=R_TqCmp_tqSumLossCmp.TqCmp_tqSumLossCmp
          dr_TqSys_bInhTqDemSptMod: data-element=R_TqSys_bInhTqDemSptMod.TqSys_bInhTqDemSptMod
          dr_TqDem_bAcvNRegTakeOff: data-element=R_TqDem_bAcvNRegTakeOff.TqDem_bAcvNRegTakeOff
          dr_AccP_rAccP: data-element=R_AccP_rAccP.AccP_rAccP
          dr_CoPt_spdVehGearRatCord: data-element=R_CoPt_spdVehGearRatCord.CoPt_spdVehGearRatCord
          dr_CoPt_bAcvProtCluP: data-element=R_CoPt_bAcvProtCluP.CoPt_bAcvProtCluP
          dr_Eng_nCkFil: data-element=R_Eng_nCkFil.Eng_nCkFil
          dr_Ext_bModSpt: data-element=R_Ext_bModSpt.Ext_bModSpt
          dr_DZone_tqEfcDifLrnOut: data-element=R_DZone_tqEfcDifLrnOut.DZone_tqEfcDifLrnOut
          dr_TqDem_rDrivTakeOff: data-element=R_TqDem_rDrivTakeOff.TqDem_rDrivTakeOff
          dr_TqDem_tqEfcNRegTakeOffEco: data-element=R_TqDem_tqEfcNRegTakeOffEco.TqDem_tqEfcNRegTakeOffEco
          dr_TqSys_nTarIdl: data-element=R_TqSys_nTarIdl.TqSys_nTarIdl
          dr_Veh_spdVeh: data-element=R_Veh_spdVeh.Veh_spdVeh
          dr_TqDem_tqEfcNRegTakeOffNorm: data-element=R_TqDem_tqEfcNRegTakeOffNorm.TqDem_tqEfcNRegTakeOffNorm
        8 x data send point:
          ds_TqDem_rAccPSptMod: data-element=P_TqDem_rAccPSptMod.TqDem_rAccPSptMod
          ds_TqDem_tqCkTakeOffMap: data-element=P_TqDem_tqCkTakeOffMap.TqDem_tqCkTakeOffMap
          ds_TqDem_tqCkEfcMin: data-element=P_TqDem_tqCkEfcMin.TqDem_tqCkEfcMin
          ds_TqDem_tqCkEfcWoutAntiDB: data-element=P_TqDem_tqCkEfcWoutAntiDB.TqDem_tqCkEfcWoutAntiDB
          ds_TqDem_tqCkEfc: data-element=P_TqDem_tqCkEfc.TqDem_tqCkEfc
          ds_TqDem_tqCkEfcMax: data-element=P_TqDem_tqCkEfcMax.TqDem_tqCkEfcMax
          ds_TqDem_bModSpt: data-element=P_TqDem_bModSpt.TqDem_bModSpt
          ds_TqDem_bTqGrdLim: data-element=P_TqDem_bTqGrdLim.TqDem_bTqGrdLim
        sync call ssp_FRM_bInhTqDemSptMod: operation=R_FRM_bInhTqDemSptMod.GetFunctionPermission
        sync call ssp_GetTimer_1ms_U32: operation=R_TqDem_GetTimer_1ms_U32.GetTimer_1ms_U32
      RE_TqDem_003_TEV: read-variable=[TqDem_tqCkEfcDeltaEcoNorm, TqDem_tqCkEfcDeltaTakeOff], written-variable=[TqDem_idxMapRvsDrv, TqDem_rTranEcoNorm, TqDem_idxMapTranDrvFirst, TqDem_rTranDrv, TqDem_idxMapTranDrvSec]  # RE_051397_10ms
        18 x data receive point:
          dr_CoPTSt_stEng: data-element=R_CoPTSt_stEng.CoPTSt_stEng
          dr_TqSys_nTarIdl: data-element=R_TqSys_nTarIdl.TqSys_nTarIdl
          dr_Ext_tCoMes: data-element=R_Ext_tCoMes.Ext_tCoMes
          dr_CoPt_idxPtSpt: data-element=R_CoPt_idxPtSpt.CoPt_idxPtSpt
          dr_Ext_stGBxCf: data-element=R_Ext_stGBxCf.Ext_stGBxCf
          dr_TqDem_bAcvNRegTakeOff: data-element=R_TqDem_bAcvNRegTakeOff.TqDem_bAcvNRegTakeOff
          dr_Ext_tOxCEstim: data-element=R_Ext_tOxCEstim.Ext_tOxCEstim
          dr_TqSys_bTypFu: data-element=R_TqSys_bTypFu.TqSys_bTypFu
          dr_Ext_bKeyOn: data-element=R_Ext_bKeyOn.Ext_bKeyOn
          dr_TqSys_bAcvAntiStall: data-element=R_TqSys_bAcvAntiStall.TqSys_bAcvAntiStall
          dr_EOM_bTWCHeatPha: data-element=R_EOM_bTWCHeatPha.EOM_bTWCHeatPha
          dr_CoPt_spdVehGearRatCord: data-element=R_CoPt_spdVehGearRatCord.CoPt_spdVehGearRatCord
          dr_Ext_nEng: data-element=R_Ext_nEng.Ext_nEng
          dr_AccP_rAccP: data-element=R_AccP_rAccP.AccP_rAccP
          dr_Veh_spdVeh: data-element=R_Veh_spdVeh.Veh_spdVeh
          dr_CoPt_bTakeOff: data-element=R_CoPt_bTakeOff.CoPt_bTakeOff
          dr_Ext_bRvs: data-element=R_Ext_bRvs.Ext_bRvs
          dr_CoPt_noEgdGearCord: data-element=R_CoPt_noEgdGearCord.CoPt_noEgdGearCord
        data send point ds_TqDem_rDrivTakeOff: data-element=P_TqDem_rDrivTakeOff.TqDem_rDrivTakeOff
        data send point ds_TqDem_bDrivTakeOff: data-element=P_TqDem_bDrivTakeOff.TqDem_bDrivTakeOff
        data send point ds_TqDem_facGainFil_nCk: data-element=P_TqDem_facGainFil_nCk.TqDem_facGainFil_nCk
        6 x sync call:
          ssp_FRM_bInhGreen_tOxCEstim: operation=R_FRM_bInhGreen_tOxCEstim.GetFunctionPermission
          ssp_FRM_bInhEco: operation=R_FRM_bInhEco.GetFunctionPermission
          ssp_FRM_bInhRvTqDemTakeOff: operation=R_FRM_bInhRvTqDemTakeOff.GetFunctionPermission
          ssp_FRM_bInhGreen_tCoMes: operation=R_FRM_bInhGreen_tCoMes.GetFunctionPermission
          ssp_FRM_bInhRvTqDemRevStOff: operation=R_FRM_bInhRvTqDemRevStOff.GetFunctionPermission
          ssp_GetTimer_1ms_U32: operation=R_TqDem_GetTimer_1ms_U32.GetTimer_1ms_U32
  swc implementation Imp_TqDem: programming-language=C, behavior=IB_TqDem
    code-descriptors:
      code CodeDescriptor: type=SRC
        10 x xfile:
          TQDEM_Coord_Xvv_c: url=TQDEM_Coord_Xvv.c
          TQDEM_Coord_Lim_Em_c: url=TQDEM_Coord_Lim_Em.c
          TQDEM_Ivc_Structure_c: url=TQDEM_Ivc_Structure.c
          TqDem_MemMap_h: url=TqDem_MemMap.h
          TqDem_c: url=TqDem.c
          TQDEM_Dzone_Torque_Calc_c: url=TQDEM_Dzone_Torque_Calc.c
          TQDEM_Trq_Take_Off_Assist_c: url=TQDEM_Trq_Take_Off_Assist.c
          TQDEM_Ivc_Content_c: url=TQDEM_Ivc_Content.c
          TqDem_h: url=TqDem.h
          TQDEM_Take_Off_Assist_c: url=TQDEM_Take_Off_Assist.c
package /Components/SWC_TqDem/TqDem_IRVDatatypes
  7 x integer type:
    DT_TqDem_idxMapRvsDrv: base-type=uint8, lower-limit=0, upper-limit=255
    DT_TqDem_idxMapTranDrvFirst: base-type=uint8, lower-limit=0, upper-limit=255
    DT_TqDem_idxMapTranDrvSec: base-type=uint8, lower-limit=0, upper-limit=255
    DT_TqDem_rTranDrv: base-type=uint16, lower-limit=0, upper-limit=65535
    DT_TqDem_rTranEcoNorm: base-type=uint16, lower-limit=0, upper-limit=65535
    DT_TqDem_tqCkEfcDeltaEcoNorm: base-type=int16, lower-limit=-32768, upper-limit=32767
    DT_TqDem_tqCkEfcDeltaTakeOff: base-type=int16, lower-limit=-32768, upper-limit=32767
